# STM32F446 register map
File version: 1.1
CPU: CM4 r1p0, little endian, no MPU, no FPU, 3 interrupt priority bits
Registers are 32-bit, read-write, reset 0x0 unless marked. A register's access mark holds for its fields unless they carry their own. Offsets are from the block's base; [hi:lo] are bit positions; {n}, {i} and the like mark numbered series.

## RCC — Reset and clock control
Base 0x40023800
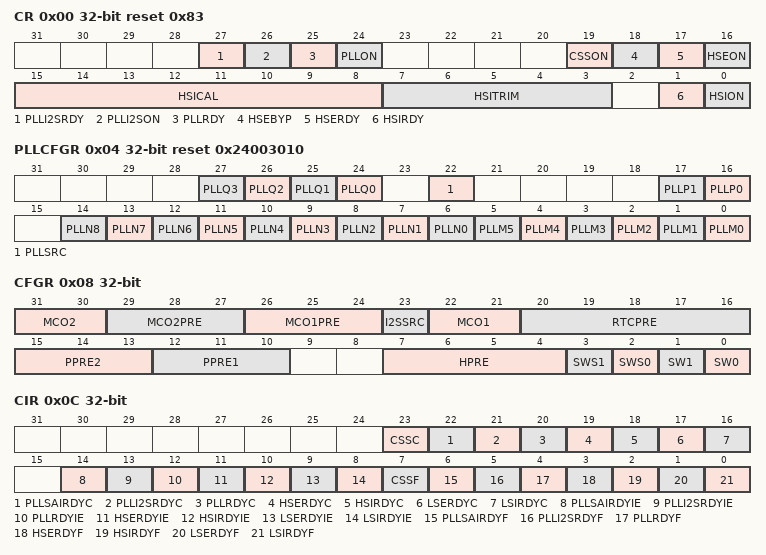
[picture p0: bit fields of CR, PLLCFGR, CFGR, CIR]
0x00 CR access per field reset 0x83 — clock control register
  [27] PLLI2SRDY ro — PLLI2S clock ready flag
  [26] PLLI2SON rw — PLLI2S enable
  [25] PLLRDY ro — Main PLL (PLL) clock ready flag
  [24] PLLON rw — Main PLL (PLL) enable
  [19] CSSON rw — Clock security system enable
  [18] HSEBYP rw — HSE clock bypass
  [17] HSERDY ro — HSE clock ready flag
  [16] HSEON rw — HSE clock enable
  [15:8] HSICAL ro — Internal high-speed clock calibration
  [7:3] HSITRIM rw — Internal high-speed clock trimming
  [1] HSIRDY ro — Internal high-speed clock ready flag
  [0] HSION rw — Internal high-speed clock enable
0x04 PLLCFGR reset 0x24003010 — PLL configuration register
  [n+24] PLLQ{n} (n=0..3) — Main PLL (PLL) division factor for USB OTG FS, SDIO and random number generator clocks
  [22] PLLSRC — Main PLL(PLL) and audio PLL (PLLI2S) entry clock source
  [17] PLLP1 — Main PLL (PLL) division factor for main system clock
  [16] PLLP0 — Main PLL (PLL) division factor for main system clock
  [n+6] PLLN{n} (n=0..8) — Main PLL (PLL) multiplication factor for VCO
  [n] PLLM{n} (n=0..5) — Division factor for the main PLL (PLL) and audio PLL (PLLI2S) input clock
0x08 CFGR access per field — clock configuration register
  [31:30] MCO2 rw — Microcontroller clock output 2
  [29:27] MCO2PRE rw — MCO2 prescaler
  [26:24] MCO1PRE rw — MCO1 prescaler
  [23] I2SSRC rw — I2S clock selection
  [22:21] MCO1 rw — Microcontroller clock output 1
  [20:16] RTCPRE rw — HSE division factor for RTC clock
  [15:13] PPRE2 rw — APB high-speed prescaler (APB2)
  [12:10] PPRE1 rw — APB Low speed prescaler (APB1)
  [7:4] HPRE rw — AHB prescaler
  [3] SWS1 ro — System clock switch status
  [2] SWS0 ro — System clock switch status
  [1] SW1 rw — System clock switch
  [0] SW0 rw — System clock switch
0x0C CIR access per field — clock interrupt register
  [23] CSSC wo — Clock security system interrupt clear
  [22] PLLSAIRDYC wo — PLLSAI Ready Interrupt Clear
  [21] PLLI2SRDYC wo — PLLI2S ready interrupt clear
  [20] PLLRDYC wo — Main PLL(PLL) ready interrupt clear
  [19] HSERDYC wo — HSE ready interrupt clear
  [18] HSIRDYC wo — HSI ready interrupt clear
  [17] LSERDYC wo — LSE ready interrupt clear
  [16] LSIRDYC wo — LSI ready interrupt clear
  [14] PLLSAIRDYIE rw — PLLSAI Ready Interrupt Enable
  [13] PLLI2SRDYIE rw — PLLI2S ready interrupt enable
  [12] PLLRDYIE rw — Main PLL (PLL) ready interrupt enable
  [11] HSERDYIE rw — HSE ready interrupt enable
  [10] HSIRDYIE rw — HSI ready interrupt enable
  [9] LSERDYIE rw — LSE ready interrupt enable
  [8] LSIRDYIE rw — LSI ready interrupt enable
  [7] CSSF ro — Clock security system interrupt flag
  [6] PLLSAIRDYF ro — PLLSAI ready interrupt flag
  [5] PLLI2SRDYF ro — PLLI2S ready interrupt flag
  [4] PLLRDYF ro — Main PLL (PLL) ready interrupt flag
  [3] HSERDYF ro — HSE ready interrupt flag
  [2] HSIRDYF ro — HSI ready interrupt flag
  [1] LSERDYF ro — LSE ready interrupt flag
  [0] LSIRDYF ro — LSI ready interrupt flag
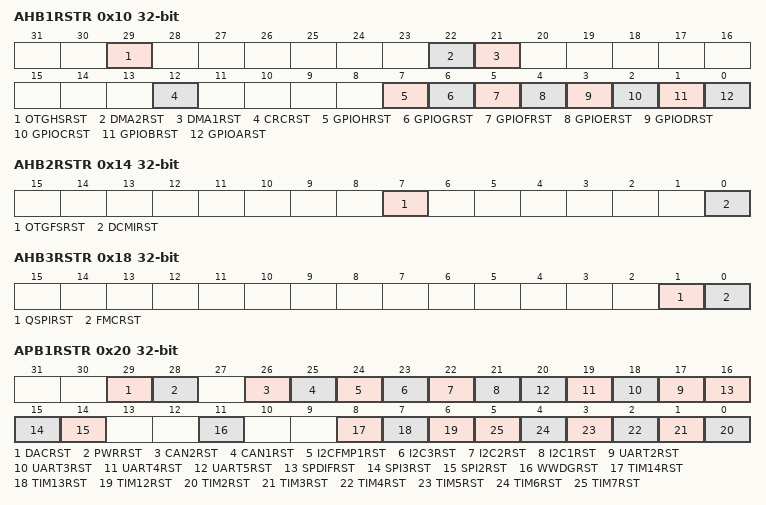
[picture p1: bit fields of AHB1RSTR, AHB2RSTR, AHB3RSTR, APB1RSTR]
0x10 AHB1RSTR — AHB1 peripheral reset register
  [29] OTGHSRST — USB OTG HS module reset
  [22] DMA2RST — DMA2 reset
  [21] DMA1RST — DMA2 reset
  [12] CRCRST — CRC reset
  [7] GPIOHRST — IO port H reset
  [6] GPIOGRST — IO port G reset
  [5] GPIOFRST — IO port F reset
  [4] GPIOERST — IO port E reset
  [3] GPIODRST — IO port D reset
  [2] GPIOCRST — IO port C reset
  [1] GPIOBRST — IO port B reset
  [0] GPIOARST — IO port A reset
0x14 AHB2RSTR — AHB2 peripheral reset register
  [7] OTGFSRST — USB OTG FS module reset
  [0] DCMIRST — Camera interface reset
0x18 AHB3RSTR — AHB3 peripheral reset register
  [1] QSPIRST — QUADSPI module reset
  [0] FMCRST — Flexible memory controller module reset
0x20 APB1RSTR — APB1 peripheral reset register
  [29] DACRST — DAC reset
  [28] PWRRST — Power interface reset
  [26] CAN2RST — CAN2 reset
  [25] CAN1RST — CAN1 reset
  [24] I2CFMP1RST — I2CFMP1 reset
  [23] I2C3RST — I2C3 reset
  [22] I2C2RST — I2C 2 reset
  [21] I2C1RST — I2C 1 reset
  [n+15] UART{n}RST (n=2..5) — USART {n} reset
  [16] SPDIFRST — SPDIF-IN reset
  [15] SPI3RST — SPI 3 reset
  [14] SPI2RST — SPI 2 reset
  [11] WWDGRST — Window watchdog reset
  [8] TIM14RST — TIM14 reset
  [7] TIM13RST — TIM13 reset
  [6] TIM12RST — TIM12 reset
  [n-2] TIM{n}RST (n=2..7) — TIM{n} reset
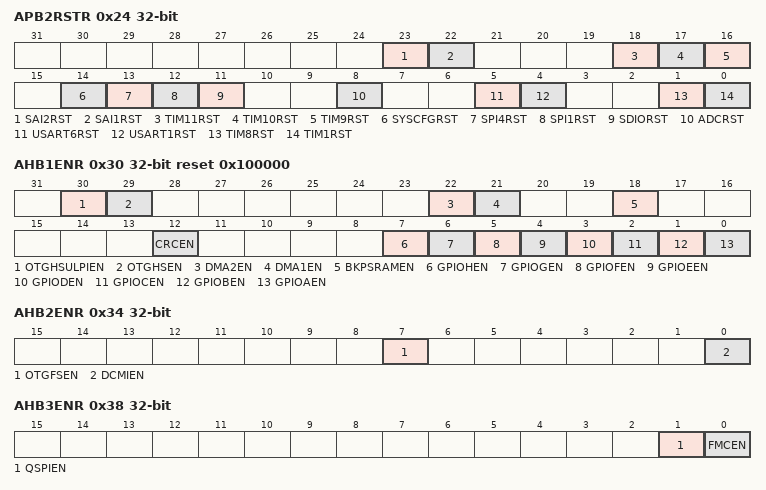
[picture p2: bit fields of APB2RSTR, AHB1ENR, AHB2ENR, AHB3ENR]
0x24 APB2RSTR — APB2 peripheral reset register
  [23] SAI2RST — SAI2 reset
  [22] SAI1RST — SAI1 reset
  [18] TIM11RST — TIM11 reset
  [17] TIM10RST — TIM10 reset
  [16] TIM9RST — TIM9 reset
  [14] SYSCFGRST — System configuration controller reset
  [13] SPI4RST — SPI4 reset
  [12] SPI1RST — SPI 1 reset
  [11] SDIORST — SDIO reset
  [8] ADCRST — ADC interface reset (common to all ADCs)
  [5] USART6RST — USART6 reset
  [4] USART1RST — USART1 reset
  [1] TIM8RST — TIM8 reset
  [0] TIM1RST — TIM1 reset
0x30 AHB1ENR reset 0x100000 — AHB1 peripheral clock register
  [30] OTGHSULPIEN — USB OTG HSULPI clock enable
  [29] OTGHSEN — USB OTG HS clock enable
  [22] DMA2EN — DMA2 clock enable
  [21] DMA1EN — DMA1 clock enable
  [18] BKPSRAMEN — Backup SRAM interface clock enable
  [12] CRCEN — CRC clock enable
  [7] GPIOHEN — IO port H clock enable
  [6] GPIOGEN — IO port G clock enable
  [5] GPIOFEN — IO port F clock enable
  [4] GPIOEEN — IO port E clock enable
  [3] GPIODEN — IO port D clock enable
  [2] GPIOCEN — IO port C clock enable
  [1] GPIOBEN — IO port B clock enable
  [0] GPIOAEN — IO port A clock enable
0x34 AHB2ENR — AHB2 peripheral clock enable register
  [7] OTGFSEN — USB OTG FS clock enable
  [0] DCMIEN — Camera interface enable
0x38 AHB3ENR — AHB3 peripheral clock enable register
  [1] QSPIEN — QUADSPI memory controller module clock enable
  [0] FMCEN — Flexible memory controller module clock enable
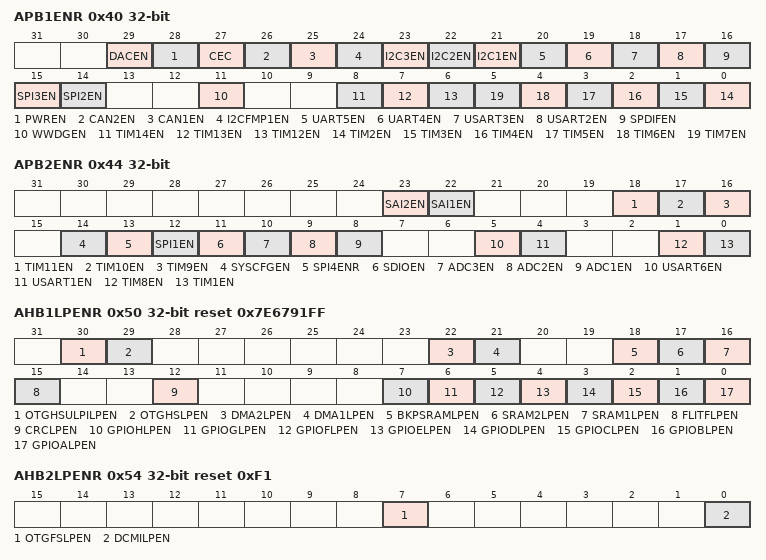
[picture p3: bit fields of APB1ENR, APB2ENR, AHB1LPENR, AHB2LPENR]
0x40 APB1ENR — APB1 peripheral clock enable register
  [29] DACEN — DAC interface clock enable
  [28] PWREN — Power interface clock enable
  [27] CEC — CEC interface clock enable
  [26] CAN2EN — CAN 2 clock enable
  [25] CAN1EN — CAN 1 clock enable
  [24] I2CFMP1EN — I2CFMP1 clock enable
  [23] I2C3EN — I2C3 clock enable
  [22] I2C2EN — I2C2 clock enable
  [21] I2C1EN — I2C1 clock enable
  [20] UART5EN — UART5 clock enable
  [19] UART4EN — UART4 clock enable
  [18] USART3EN — USART3 clock enable
  [17] USART2EN — USART 2 clock enable
  [16] SPDIFEN — SPDIF-IN clock enable
  [15] SPI3EN — SPI3 clock enable
  [14] SPI2EN — SPI2 clock enable
  [11] WWDGEN — Window watchdog clock enable
  [8] TIM14EN — TIM14 clock enable
  [7] TIM13EN — TIM13 clock enable
  [6] TIM12EN — TIM12 clock enable
  [n-2] TIM{n}EN (n=2..7) — TIM{n} clock enable
0x44 APB2ENR — APB2 peripheral clock enable register
  [23] SAI2EN — SAI2 clock enable
  [22] SAI1EN — SAI1 clock enable
  [18] TIM11EN — TIM11 clock enable
  [17] TIM10EN — TIM10 clock enable
  [16] TIM9EN — TIM9 clock enable
  [14] SYSCFGEN — System configuration controller clock enable
  [13] SPI4ENR — SPI4 clock enable
  [12] SPI1EN — SPI1 clock enable
  [11] SDIOEN — SDIO clock enable
  [10] ADC3EN — ADC3 clock enable
  [9] ADC2EN — ADC2 clock enable
  [8] ADC1EN — ADC1 clock enable
  [5] USART6EN — USART6 clock enable
  [4] USART1EN — USART1 clock enable
  [1] TIM8EN — TIM8 clock enable
  [0] TIM1EN — TIM1 clock enable
0x50 AHB1LPENR reset 0x7E6791FF — AHB1 peripheral clock enable in low power mode register
  [30] OTGHSULPILPEN — USB OTG HS ULPI clock enable during Sleep mode
  [29] OTGHSLPEN — USB OTG HS clock enable during Sleep mode
  [22] DMA2LPEN — DMA2 clock enable during Sleep mode
  [21] DMA1LPEN — DMA1 clock enable during Sleep mode
  [18] BKPSRAMLPEN — Backup SRAM interface clock enable during Sleep mode
  [17] SRAM2LPEN — SRAM 2 interface clock enable during Sleep mode
  [16] SRAM1LPEN — SRAM 1interface clock enable during Sleep mode
  [15] FLITFLPEN — Flash interface clock enable during Sleep mode
  [12] CRCLPEN — CRC clock enable during Sleep mode
  [7] GPIOHLPEN — IO port H clock enable during Sleep mode
  [6] GPIOGLPEN — IO port G clock enable during Sleep mode
  [5] GPIOFLPEN — IO port F clock enable during Sleep mode
  [4] GPIOELPEN — IO port E clock enable during Sleep mode
  [3] GPIODLPEN — IO port D clock enable during Sleep mode
  [2] GPIOCLPEN — IO port C clock enable during Sleep mode
  [1] GPIOBLPEN — IO port B clock enable during Sleep mode
  [0] GPIOALPEN — IO port A clock enable during sleep mode
0x54 AHB2LPENR reset 0xF1 — AHB2 peripheral clock enable in low power mode register
  [7] OTGFSLPEN — USB OTG FS clock enable during Sleep mode
  [0] DCMILPEN — Camera interface enable during Sleep mode
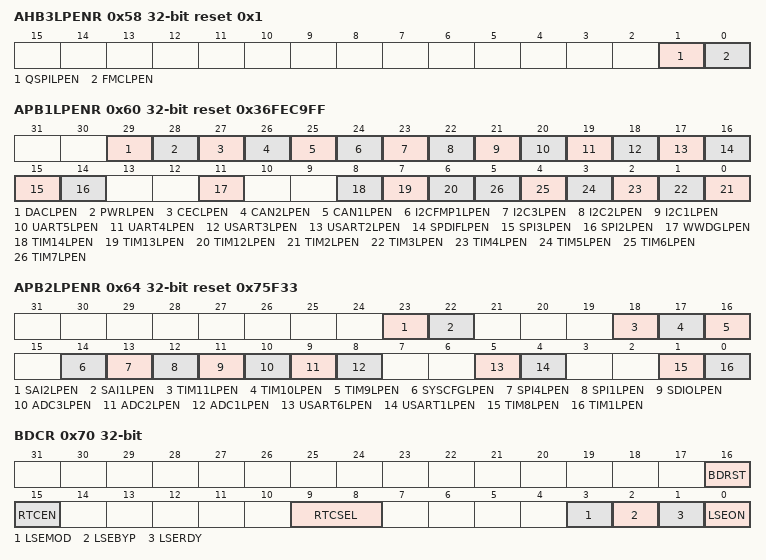
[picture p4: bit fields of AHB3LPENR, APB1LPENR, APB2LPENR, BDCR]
0x58 AHB3LPENR reset 0x1 — AHB3 peripheral clock enable in low power mode register
  [1] QSPILPEN — QUADSPI memory controller module clock enable during Sleep mode
  [0] FMCLPEN — Flexible memory controller module clock enable during Sleep mode
0x60 APB1LPENR reset 0x36FEC9FF — APB1 peripheral clock enable in low power mode register
  [29] DACLPEN — DAC interface clock enable during Sleep mode
  [28] PWRLPEN — Power interface clock enable during Sleep mode
  [27] CECLPEN — CEC clock enable during Sleep mode
  [26] CAN2LPEN — CAN 2 clock enable during Sleep mode
  [25] CAN1LPEN — CAN 1 clock enable during Sleep mode
  [24] I2CFMP1LPEN — I2CFMP1 clock enable during Sleep mode
  [23] I2C3LPEN — I2C3 clock enable during Sleep mode
  [22] I2C2LPEN — I2C2 clock enable during Sleep mode
  [21] I2C1LPEN — I2C1 clock enable during Sleep mode
  [20] UART5LPEN — UART5 clock enable during Sleep mode
  [19] UART4LPEN — UART4 clock enable during Sleep mode
  [18] USART3LPEN — USART3 clock enable during Sleep mode
  [17] USART2LPEN — USART2 clock enable during Sleep mode
  [16] SPDIFLPEN — SPDIF clock enable during Sleep mode
  [15] SPI3LPEN — SPI3 clock enable during Sleep mode
  [14] SPI2LPEN — SPI2 clock enable during Sleep mode
  [11] WWDGLPEN — Window watchdog clock enable during Sleep mode
  [8] TIM14LPEN — TIM14 clock enable during Sleep mode
  [7] TIM13LPEN — TIM13 clock enable during Sleep mode
  [6] TIM12LPEN — TIM12 clock enable during Sleep mode
  [n-2] TIM{n}LPEN (n=2..7) — TIM{n} clock enable during Sleep mode
0x64 APB2LPENR reset 0x75F33 — APB2 peripheral clock enabled in low power mode register
  [23] SAI2LPEN — SAI2 clock enable
  [22] SAI1LPEN — SAI1 clock enable
  [18] TIM11LPEN — TIM11 clock enable during Sleep mode
  [17] TIM10LPEN — TIM10 clock enable during Sleep mode
  [16] TIM9LPEN — TIM9 clock enable during sleep mode
  [14] SYSCFGLPEN — System configuration controller clock enable during Sleep mode
  [13] SPI4LPEN — SPI 4 clock enable during Sleep mode
  [12] SPI1LPEN — SPI 1 clock enable during Sleep mode
  [11] SDIOLPEN — SDIO clock enable during Sleep mode
  [10] ADC3LPEN — ADC 3 clock enable during Sleep mode
  [9] ADC2LPEN — ADC2 clock enable during Sleep mode
  [8] ADC1LPEN — ADC1 clock enable during Sleep mode
  [5] USART6LPEN — USART6 clock enable during Sleep mode
  [4] USART1LPEN — USART1 clock enable during Sleep mode
  [1] TIM8LPEN — TIM8 clock enable during Sleep mode
  [0] TIM1LPEN — TIM1 clock enable during Sleep mode
0x70 BDCR access per field — Backup domain control register
  [16] BDRST rw — Backup domain software reset
  [15] RTCEN rw — RTC clock enable
  [9:8] RTCSEL rw — RTC clock source selection
  [3] LSEMOD rw — External low-speed oscillator mode
  [2] LSEBYP rw — External low-speed oscillator bypass
  [1] LSERDY ro — External low-speed oscillator ready
  [0] LSEON rw — External low-speed oscillator enable
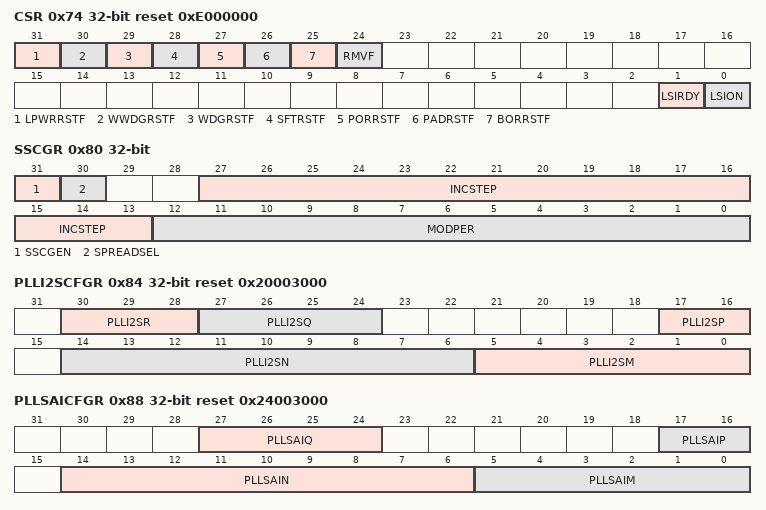
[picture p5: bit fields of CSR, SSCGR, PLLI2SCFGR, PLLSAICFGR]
0x74 CSR access per field reset 0xE000000 — clock control & status register
  [31] LPWRRSTF rw — Low-power reset flag
  [30] WWDGRSTF rw — Window watchdog reset flag
  [29] WDGRSTF rw — Independent watchdog reset flag
  [28] SFTRSTF rw — Software reset flag
  [27] PORRSTF rw — POR/PDR reset flag
  [26] PADRSTF rw — PIN reset flag
  [25] BORRSTF rw — BOR reset flag
  [24] RMVF rw — Remove reset flag
  [1] LSIRDY ro — Internal low-speed oscillator ready
  [0] LSION rw — Internal low-speed oscillator enable
0x80 SSCGR — spread spectrum clock generation register
  [31] SSCGEN — Spread spectrum modulation enable
  [30] SPREADSEL — Spread Select
  [27:13] INCSTEP — Incrementation step
  [12:0] MODPER — Modulation period
0x84 PLLI2SCFGR reset 0x20003000 — PLLI2S configuration register
  [30:28] PLLI2SR — PLLI2S division factor for I2S clocks
  [27:24] PLLI2SQ — PLLI2S division factor for SAI1 clock
  [17:16] PLLI2SP — PLLI2S division factor for SPDIF-IN clock
  [14:6] PLLI2SN — PLLI2S multiplication factor for VCO
  [5:0] PLLI2SM — Division factor for audio PLL (PLLI2S) input clock
0x88 PLLSAICFGR reset 0x24003000 — PLL configuration register
  [27:24] PLLSAIQ — PLLSAI division factor for SAIs clock
  [17:16] PLLSAIP — PLLSAI division factor for 48 MHz clock
  [14:6] PLLSAIN — PLLSAI division factor for VCO
  [5:0] PLLSAIM — Division factor for audio PLLSAI input clock
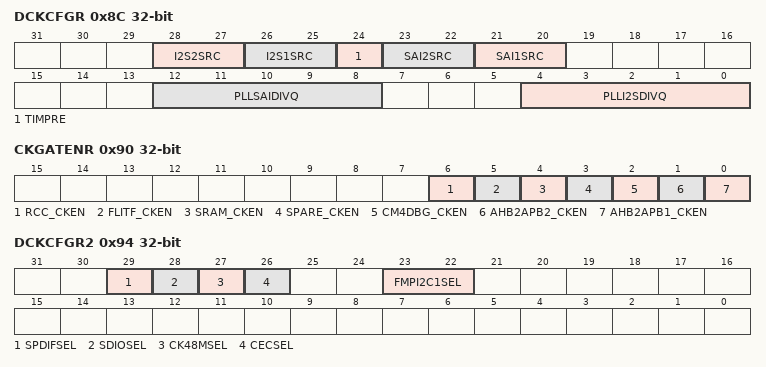
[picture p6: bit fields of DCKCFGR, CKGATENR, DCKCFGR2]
0x8C DCKCFGR — Dedicated Clock Configuration Register
  [28:27] I2S2SRC — I2S APB2 clock source selection
  [26:25] I2S1SRC — I2S APB1 clock source selection
  [24] TIMPRE — Timers clocks prescalers selection
  [23:22] SAI2SRC — SAI2 clock source selection
  [21:20] SAI1SRC — SAI1 clock source selection
  [12:8] PLLSAIDIVQ — PLLSAI division factor for SAIs clock
  [4:0] PLLI2SDIVQ — PLLI2S division factor for SAIs clock
0x90 CKGATENR — clocks gated enable register
  [6] RCC_CKEN — RCC clock enable
  [5] FLITF_CKEN — Flash Interface clock enable
  [4] SRAM_CKEN — SRQAM controller clock enable
  [3] SPARE_CKEN — Spare clock enable
  [2] CM4DBG_CKEN — Cortex M4 ETM clock enable
  [1] AHB2APB2_CKEN — AHB to APB2 Bridge clock enable
  [0] AHB2APB1_CKEN — AHB to APB1 Bridge clock enable
0x94 DCKCFGR2 — dedicated clocks configuration register 2
  [29] SPDIFSEL — SPDIF clock selection
  [28] SDIOSEL — SDIO clock selection
  [27] CK48MSEL — SDIO/USBFS/HS clock selection
  [26] CECSEL — HDMI CEC clock source selection
  [23:22] FMPI2C1SEL — I2C4 kernel clock source selection
